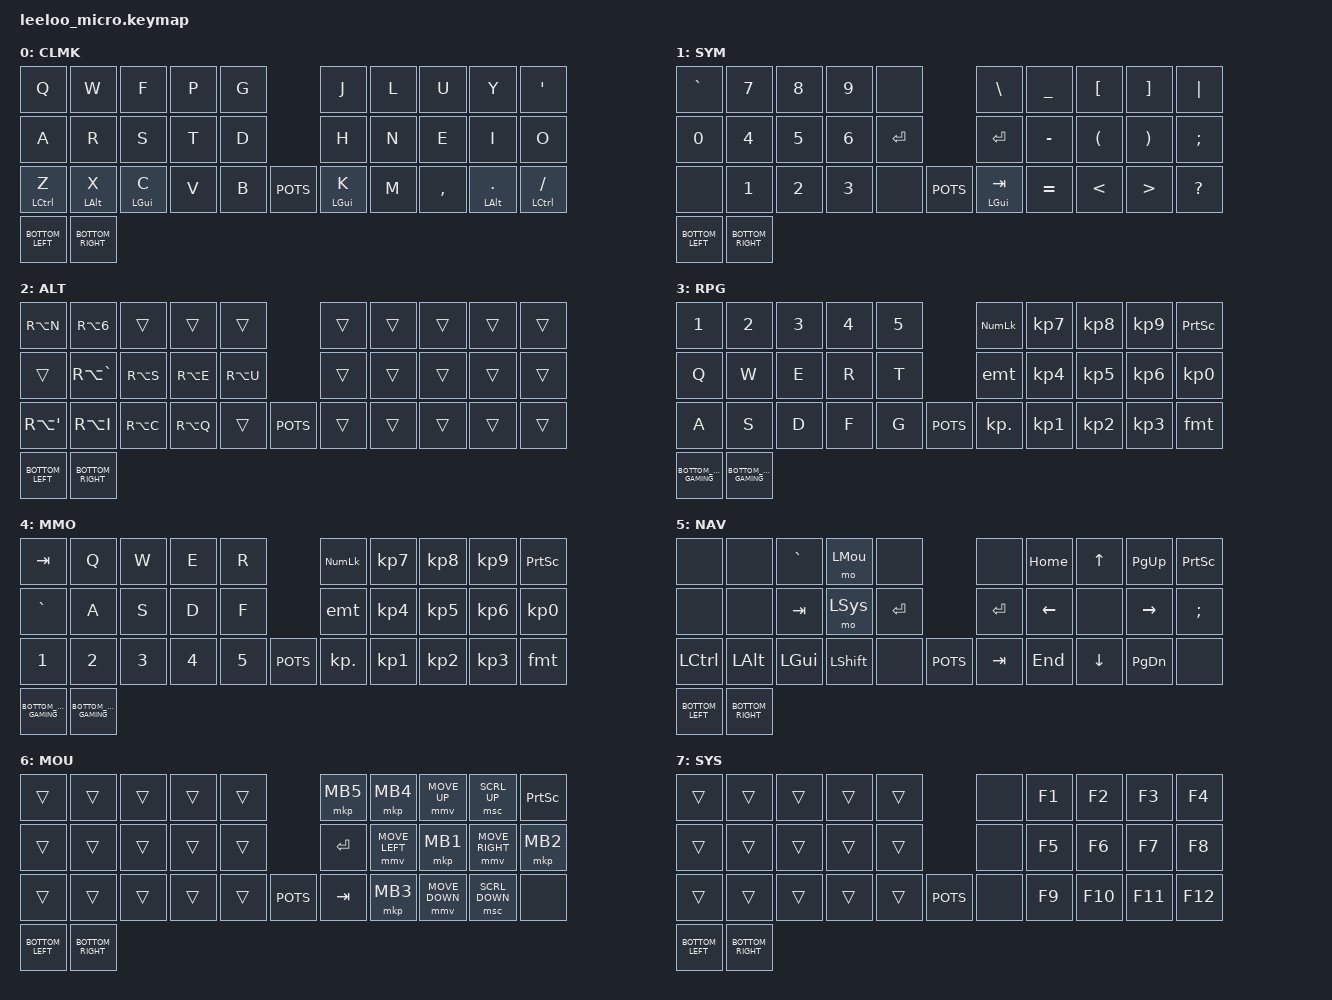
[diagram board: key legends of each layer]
#include <behaviors.dtsi>
#include <dt-bindings/zmk/outputs.h>
#include <dt-bindings/zmk/keys.h>
#include <dt-bindings/zmk/bt.h>
#include <dt-bindings/zmk/rgb.h>
#include <dt-bindings/zmk/pointing.h>

#define ZMK_POINTING_DEFAULT_MOVE_VAL 500
#define ZMK_POINTING_DEFAULT_SCRL_VAL 20

// Layers
#define LTyp 0
#define LSym 1
#define LAlt 2
#define LRPG 3
#define LMMO 4
#define LNav 5
#define LMou 6
#define LSys 7

#define BOTTOM_LEFT           &mo LSys                  &kp BACKSPACE   &stck_lay LSym LSym      &lt LNav ESC
#define BOTTOM_LEFT_GAMING    &kp LALT                  &kp LSHIFT      &kp LCTL                 &lt LNav ESC     
#define BOTTOM_RIGHT          &stck_mod LSHIFT LSHIFT   &kp SPACE       &kp DELETE               &lt LAlt INSERT
#define BOTTOM_RIGHT_GAMING   &mo LSys                  &kp SPACE       &kp BACKSPACE            &lt LSys TAB
#define POTS &out OUT_TOG &kp C_MUTE

nice_view_spi: &spi0 {
  compatible = "nordic,nrf-spim";
  pinctrl-0 = <&spi0_default>;
  pinctrl-1 = <&spi0_sleep>;
  pinctrl-names = "default", "sleep";
  cs-gpios = <&pro_micro 4 GPIO_ACTIVE_HIGH>;
};

&mt {
    tapping-term-ms = <200>;
    flavor = "tap-preferred";
    quick-tap-ms = <0>;
};

&lt {
    tapping-term-ms = <200>;
    quick-tap-ms = <0>;
};

&sensors {
    left_config {
        triggers-per-rotation = <30>;
    };
    right_config {
        triggers-per-rotation = <30>;
    };
};

/ {
    behaviors {
        stck_mod: sticky_hold_mod {
            compatible = "zmk,behavior-hold-tap";
            label = "STICKY_HOLD_MOD";
            #binding-cells = <2>;
            bindings = <&kp>, <&sk>;
            tapping-term-ms = <200>;
        };

        stck_lay: sticky_hold_layer {
            compatible = "zmk,behavior-hold-tap";
            label = "STICKY_HOLD_LAYER";
            #binding-cells = <2>;
            bindings = <&mo>, <&sl>;
            tapping-term-ms = <200>;
        };

        ZMK_MACRO(fslh_typ,
            wait-ms = <0>;
            tap-ms = <0>;
            bindings = <&kp FSLH &to LTyp>;
        )

        fmt: fslh_mod_typ {
            compatible = "zmk,behavior-mod-morph";
            label = "FSLH_MOD_TYP";
            #binding-cells = <0>;
            bindings = <&kp FSLH>, <&fslh_typ>;
            mods = <(MOD_LCTL|MOD_LSFT)>;
        };

        ZMK_MACRO(enter_typ,
            wait-ms = <0>;
            tap-ms = <0>;
            bindings = <&kp ENTER &to LTyp>;
        )

        emt: enter_mod_typ {
            compatible = "zmk,behavior-mod-morph";
            label = "ENTER_MOD_TYP";
            #binding-cells = <0>;
            bindings = <&kp ENTER>, <&enter_typ>;
            mods = <(MOD_LCTL|MOD_LSFT)>;
        };

        vol_enc: change_volume_encoder {
            compatible = "zmk,behavior-sensor-rotate";
            #sensor-binding-cells = <0>;
            bindings = <&kp C_VOL_UP>, <&kp C_VOL_DN>;
        };

        layer_enc: change_layer_encoder {
            compatible = "zmk,behavior-sensor-rotate-var";
            #sensor-binding-cells = <2>;
            bindings = <&to>, <&to>;
        };
    };

    keymap {
        compatible = "zmk,keymap";

        layer_main {
            label = "CLMK";
            sensor-bindings = <&layer_enc LRPG LTyp &vol_enc>;
            bindings = <
&kp Q        &kp W        &kp F        &kp P   &kp G          &kp J        &kp L   &kp U       &kp Y          &kp APOS
&kp A        &kp R        &kp S        &kp T   &kp D          &kp H        &kp N   &kp E       &kp I          &kp O   
&mt LCTL Z   &mt LALT X   &mt LGUI C   &kp V   &kp B   POTS   &mt LGUI K   &kp M   &kp COMMA   &mt LALT DOT   &mt LCTL FSLH
BOTTOM_LEFT BOTTOM_RIGHT
            >;
        };

        layer_symbols {
            label = "SYM";
            bindings = <
&kp GRAVE   &kp N7   &kp N8   &kp N9   &none              &kp BSLH       &kp UNDER   &kp LBKT   &kp RBKT   &kp PIPE
&kp N0      &kp N4   &kp N5   &kp N6   &kp ENTER          &kp ENTER      &kp MINUS   &kp LPAR   &kp RPAR   &kp SEMI
&none       &kp N1   &kp N2   &kp N3   &none       POTS   &mt LGUI TAB   &kp EQUAL   &kp LT     &kp GT     &kp QMARK
BOTTOM_LEFT BOTTOM_RIGHT
            >;
        };

        layer_right_alt {
            label = "ALT";
            bindings = <
&kp RA(N)      &kp RA(N6)      &trans      &trans      &trans             &trans   &trans   &trans   &trans   &trans
&trans         &kp RA(GRAVE)   &kp RA(S)   &kp RA(E)   &kp RA(U)          &trans   &trans   &trans   &trans   &trans
&kp RA(APOS)   &kp RA(I)       &kp RA(C)   &kp RA(Q)   &trans      POTS   &trans   &trans   &trans   &trans   &trans
BOTTOM_LEFT BOTTOM_RIGHT
            >;
        };

        layer_gaming_arpg {
            label = "RPG";
            sensor-bindings = <&layer_enc LMMO LTyp &vol_enc>;
            bindings = <
&kp N1   &kp N2   &kp N3   &kp N4   &kp N5          &kp KP_NUMLOCK   &kp KP_N7   &kp KP_N8   &kp KP_N9   &kp PSCRN
&kp Q    &kp W    &kp E    &kp R    &kp T           &emt             &kp KP_N4   &kp KP_N5   &kp KP_N6   &kp KP_N0 
&kp A    &kp S    &kp D    &kp F    &kp G    POTS   &kp KP_DOT       &kp KP_N1   &kp KP_N2   &kp KP_N3   &fmt
BOTTOM_LEFT_GAMING BOTTOM_RIGHT_GAMING
            >;
        };

        layer_gaming_mmo {
            label = "MMO";
            sensor-bindings = <&layer_enc LRPG LTyp &vol_enc>;
            bindings = <
&kp TAB     &kp Q    &kp W    &kp E    &kp R           &kp KP_NUMLOCK   &kp KP_N7   &kp KP_N8   &kp KP_N9   &kp PSCRN
&kp GRAVE   &kp A    &kp S    &kp D    &kp F           &emt             &kp KP_N4   &kp KP_N5   &kp KP_N6   &kp KP_N0 
&kp N1      &kp N2   &kp N3   &kp N4   &kp N5   POTS   &kp KP_DOT       &kp KP_N1   &kp KP_N2   &kp KP_N3   &fmt 
BOTTOM_LEFT_GAMING BOTTOM_RIGHT_GAMING
            >;
        };

        layer_navigation {
            label = "NAV";
            bindings = <
&none      &none      &kp GRAVE   &mo LMou     &none              &none       &kp HOME   &kp UP     &kp PAGE_UP     &kp PSCRN  
&none      &none      &kp TAB     &mo LSys     &kp ENTER          &kp ENTER   &kp LEFT   &none      &kp RIGHT       &kp SEMI
&kp LCTL   &kp LALT   &kp LGUI    &kp LSHIFT   &none       POTS   &kp TAB     &kp END    &kp DOWN   &kp PAGE_DOWN   &none
BOTTOM_LEFT BOTTOM_RIGHT
            >;
        };

        layer_mouse {
            label = "MOU";
            bindings = <
&trans   &trans   &trans   &trans   &trans          &mkp MB5    &mkp MB4         &mmv MOVE_UP     &msc SCRL_UP      &kp PSCRN  
&trans   &trans   &trans   &trans   &trans          &kp ENTER   &mmv MOVE_LEFT   &mkp MB1         &mmv MOVE_RIGHT   &mkp MB2
&trans   &trans   &trans   &trans   &trans   POTS   &kp TAB     &mkp MB3         &mmv MOVE_DOWN   &msc SCRL_DOWN    &none
BOTTOM_LEFT BOTTOM_RIGHT
            >;
        };

        layer_system {
            label = "SYS";
            bindings = <
&trans   &trans   &trans   &trans   &trans         &none   &kp F1   &kp F2    &kp F3    &kp F4
&trans   &trans   &trans   &trans   &trans         &none   &kp F5   &kp F6    &kp F7    &kp F8
&trans   &trans   &trans   &trans   &trans  POTS   &none   &kp F9   &kp F10   &kp F11   &kp F12
BOTTOM_LEFT BOTTOM_RIGHT
            >;
        };
    };
};
